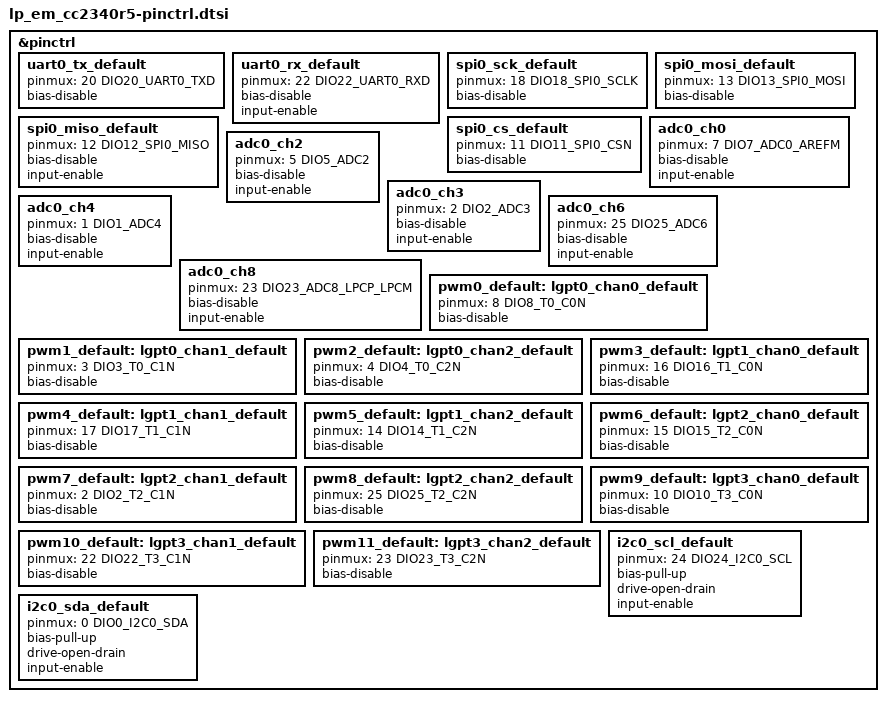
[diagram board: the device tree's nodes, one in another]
/*
 * Copyright (c) 2024 Texas Instruments Incorporated
 * Copyright (c) 2024 BayLibre, SAS
 *
 * SPDX-License-Identifier: Apache-2.0
 */

#include <zephyr/dt-bindings/pinctrl/cc23x0-pinctrl.h>

&pinctrl {
	/* UART0 */
	uart0_tx_default: uart0_tx_default {
		pinmux = <20 DIO20_UART0_TXD>;
		bias-disable;
	};

	uart0_rx_default: uart0_rx_default {
		pinmux = <22 DIO22_UART0_RXD>;
		bias-disable;
		input-enable;
	};

	/* SPI0 */
	spi0_sck_default: spi0_sck_default {
		pinmux = <18 DIO18_SPI0_SCLK>;
		bias-disable;
	};

	spi0_mosi_default: spi0_mosi_default {
		pinmux = <13 DIO13_SPI0_MOSI>;
		bias-disable;
	};

	spi0_miso_default: spi0_miso_default {
		pinmux = <12 DIO12_SPI0_MISO>;
		bias-disable;
		input-enable;
	};

	spi0_cs_default: spi0_cs_default {
		pinmux = <11 DIO11_SPI0_CSN>;
		bias-disable;
	};

	/* ADC0 */
	adc0_ch0: adc0_ch0 {
		pinmux = <7 DIO7_ADC0_AREFM>;
		bias-disable;
		input-enable;
	};

	adc0_ch2: adc0_ch2 {
		pinmux = <5 DIO5_ADC2>;
		bias-disable;
		input-enable;
	};

	adc0_ch3: adc0_ch3 {
		pinmux = <2 DIO2_ADC3>;
		bias-disable;
		input-enable;
	};

	adc0_ch4: adc0_ch4 {
		pinmux = <1 DIO1_ADC4>;
		bias-disable;
		input-enable;
	};

	adc0_ch6: adc0_ch6 {
		pinmux = <25 DIO25_ADC6>;
		bias-disable;
		input-enable;
	};

	adc0_ch8: adc0_ch8 {
		pinmux = <23 DIO23_ADC8_LPCP_LPCM>;
		bias-disable;
		input-enable;
	};

	/* LGPT0 - PWM */
	pwm0_default: lgpt0_chan0_default {
		pinmux = <8 DIO8_T0_C0N>;
		bias-disable;
	};

	pwm1_default: lgpt0_chan1_default {
		pinmux = <3 DIO3_T0_C1N>;
		bias-disable;
	};

	pwm2_default: lgpt0_chan2_default {
		pinmux = <4 DIO4_T0_C2N>;
		bias-disable;
	};

	/* LGPT1 - PWM */
	pwm3_default: lgpt1_chan0_default {
		pinmux = <16 DIO16_T1_C0N>;
		bias-disable;
	};

	pwm4_default: lgpt1_chan1_default {
		pinmux = <17 DIO17_T1_C1N>;
		bias-disable;
	};

	pwm5_default: lgpt1_chan2_default {
		pinmux = <14 DIO14_T1_C2N>;
		bias-disable;
	};

	/* LGPT2 - PWM */
	pwm6_default: lgpt2_chan0_default {
		pinmux = <15 DIO15_T2_C0N>;
		bias-disable;
	};

	pwm7_default: lgpt2_chan1_default {
		pinmux = <2 DIO2_T2_C1N>;
		bias-disable;
	};

	pwm8_default: lgpt2_chan2_default {
		pinmux = <25 DIO25_T2_C2N>;
		bias-disable;
	};

	/* LGPT3 - PWM */
	pwm9_default: lgpt3_chan0_default {
		pinmux = <10 DIO10_T3_C0N>;
		bias-disable;
	};

	pwm10_default: lgpt3_chan1_default {
		pinmux = <22 DIO22_T3_C1N>;
		bias-disable;
	};

	pwm11_default: lgpt3_chan2_default {
		pinmux = <23 DIO23_T3_C2N>;
		bias-disable;
	};

	/* I2C0 */
	i2c0_scl_default: i2c0_scl_default {
		pinmux = <24 DIO24_I2C0_SCL>;
		bias-pull-up;
		drive-open-drain;
		input-enable;
	};
	i2c0_sda_default: i2c0_sda_default {
		pinmux = <0 DIO0_I2C0_SDA>;
		bias-pull-up;
		drive-open-drain;
		input-enable;
	};
};
